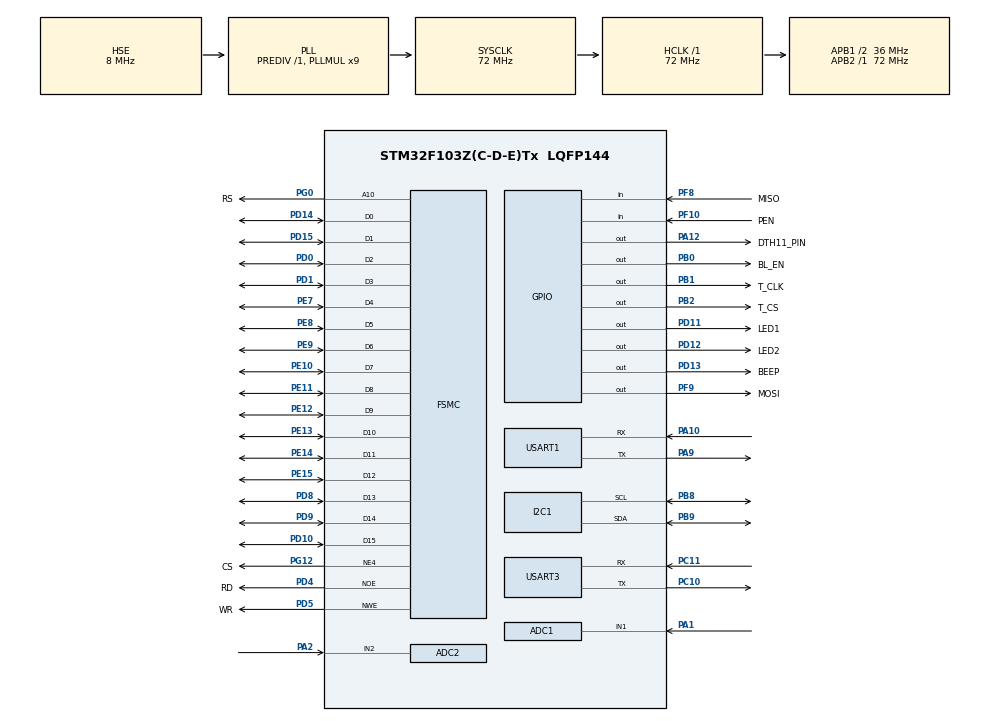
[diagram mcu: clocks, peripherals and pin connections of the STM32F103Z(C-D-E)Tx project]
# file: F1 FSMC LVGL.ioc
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ADC1.Channel-0\#ChannelRegularConversion=ADC_CHANNEL_1
ADC1.NbrOfConversionFlag=1
ADC1.Rank-0\#ChannelRegularConversion=1
ADC1.SamplingTime-0\#ChannelRegularConversion=ADC_SAMPLETIME_1CYCLE_5
ADC1.master=1
ADC2.Channel-1\#ChannelRegularConversion=ADC_CHANNEL_2
ADC2.NbrOfConversionFlag=1
ADC2.Rank-1\#ChannelRegularConversion=1
ADC2.SamplingTime-1\#ChannelRegularConversion=ADC_SAMPLETIME_1CYCLE_5
FREERTOS.HEAP_NUMBER=4
FREERTOS.Tasks01=defaultTask,24,128,StartDefaultTask,Default,NULL,Dynamic,NULL,NULL
FREERTOS.configCHECK_FOR_STACK_OVERFLOW=2
FREERTOS.configTOTAL_HEAP_SIZE=20480
FREERTOS.configUSE_MALLOC_FAILED_HOOK=1
FREERTOS.configUSE_TICK_HOOK=1
FSMC.AddressSetupTime1=0
FSMC.BusTurnAroundDuration1=0
FSMC.DataSetupTime1=26
FSMC.ExtendedAddressSetupTime1=0
FSMC.ExtendedBusTurnAroundDuration1=0
FSMC.ExtendedDataSetupTime1=1
FSMC.ExtendedMode1=FSMC_EXTENDED_MODE_ENABLE
Mcu.Family=STM32F1
Mcu.Name=STM32F103Z(C-D-E)Tx
Mcu.Package=LQFP144
NVIC.ADC1_2_IRQn=true\:5\:0\:false\:false\:true\:true\:true\:true\:true
NVIC.I2C1_ER_IRQn=true\:5\:0\:false\:false\:true\:true\:true\:true\:true
NVIC.I2C1_EV_IRQn=true\:5\:0\:false\:false\:true\:true\:true\:true\:true
NVIC.PriorityGroup=NVIC_PRIORITYGROUP_4
NVIC.RTC_IRQn=true\:5\:0\:false\:false\:true\:true\:true\:true\:true
NVIC.TIM1_UP_IRQn=true\:15\:0\:false\:false\:true\:false\:false\:true\:true
NVIC.TIM3_IRQn=true\:5\:0\:false\:false\:true\:true\:true\:true\:true
NVIC.TimeBase=TIM1_UP_IRQn
NVIC.TimeBaseIP=TIM1
NVIC.USART1_IRQn=true\:5\:0\:false\:false\:true\:true\:true\:true\:true
NVIC.USART3_IRQn=true\:5\:0\:false\:false\:true\:true\:true\:true\:true
OSC_IN.Mode=HSE-External-Oscillator
OSC_IN.Signal=RCC_OSC_IN
OSC_OUT.Mode=HSE-External-Oscillator
OSC_OUT.Signal=RCC_OSC_OUT
PA1.Signal=ADCx_IN1
PA10.Mode=Asynchronous
PA10.Signal=USART1_RX
PA12.GPIO_Label=DTH11_PIN
PA12.Signal=GPIO_Output
PA13.Mode=Serial_Wire
PA13.Signal=SYS_JTMS-SWDIO
PA14.Mode=Serial_Wire
PA14.Signal=SYS_JTCK-SWCLK
PA2.Signal=ADCx_IN2
PA9.Mode=Asynchronous
PA9.Signal=USART1_TX
PB0.GPIO_Label=BL_EN
PB0.GPIO_PuPd=GPIO_PULLUP
PB0.GPIO_Speed=GPIO_SPEED_FREQ_HIGH
PB0.Signal=GPIO_Output
PB1.GPIO_Label=T_CLK
PB1.GPIO_PuPd=GPIO_PULLUP
PB1.GPIO_Speed=GPIO_SPEED_FREQ_HIGH
PB1.PinState=GPIO_PIN_SET
PB1.Signal=GPIO_Output
PB2.GPIO_Label=T_CS
PB2.GPIO_PuPd=GPIO_PULLUP
PB2.GPIO_Speed=GPIO_SPEED_FREQ_HIGH
PB2.PinState=GPIO_PIN_SET
PB2.Signal=GPIO_Output
PB8.Mode=I2C
PB8.Signal=I2C1_SCL
PB9.Mode=I2C
PB9.Signal=I2C1_SDA
PC10.Mode=Asynchronous
PC10.Signal=USART3_TX
PC11.Mode=Asynchronous
PC11.Signal=USART3_RX
PC14-OSC32_IN.Mode=LSE-External-Oscillator
PC14-OSC32_IN.Signal=RCC_OSC32_IN
PC15-OSC32_OUT.Mode=LSE-External-Oscillator
PC15-OSC32_OUT.Signal=RCC_OSC32_OUT
PD0.Signal=FSMC_D2_DA2
PD1.Signal=FSMC_D3_DA3
PD10.Signal=FSMC_D15_DA15
PD11.GPIO_Label=LED1
PD11.GPIO_Speed=GPIO_SPEED_FREQ_MEDIUM
PD11.PinState=GPIO_PIN_SET
PD11.Signal=GPIO_Output
PD12.GPIO_Label=LED2
PD12.GPIO_Speed=GPIO_SPEED_FREQ_MEDIUM
PD12.PinState=GPIO_PIN_SET
PD12.Signal=GPIO_Output
PD13.GPIO_Label=BEEP
PD13.GPIO_Speed=GPIO_SPEED_FREQ_MEDIUM
PD13.PinState=GPIO_PIN_SET
PD13.Signal=GPIO_Output
PD14.Signal=FSMC_D0_DA0
PD15.Signal=FSMC_D1_DA1
PD4.GPIO_Label=RD
PD4.Signal=FSMC_NOE
PD5.GPIO_Label=WR
PD5.Signal=FSMC_NWE
PD8.Signal=FSMC_D13_DA13
PD9.Signal=FSMC_D14_DA14
PE10.Signal=FSMC_D7_DA7
PE11.Signal=FSMC_D8_DA8
PE12.Signal=FSMC_D9_DA9
PE13.Signal=FSMC_D10_DA10
PE14.Signal=FSMC_D11_DA11
PE15.Signal=FSMC_D12_DA12
PE7.Signal=FSMC_D4_DA4
PE8.Signal=FSMC_D5_DA5
PE9.Signal=FSMC_D6_DA6
PF10.GPIO_Label=PEN
PF10.GPIO_PuPd=GPIO_PULLUP
PF10.Signal=GPIO_Input
PF8.GPIO_Label=MISO
PF8.Signal=GPIO_Input
PF9.GPIO_Label=MOSI
PF9.GPIO_PuPd=GPIO_PULLUP
PF9.GPIO_Speed=GPIO_SPEED_FREQ_HIGH
PF9.PinState=GPIO_PIN_SET
PF9.Signal=GPIO_Output
PG0.GPIO_Label=RS
PG0.Signal=FSMC_A10
PG12.GPIO_Label=CS
PG12.Mode=NorPsramChipSelect4_1
PG12.Signal=FSMC_NE4
ProjectManager.HeapSize=0x200
ProjectManager.StackSize=0x400
ProjectManager.TargetToolchain=MDK-ARM V5.32
RCC.ADCPresc=RCC_ADCPCLK2_DIV6
RCC.AHBFreq_Value=72000000
RCC.APB1CLKDivider=RCC_HCLK_DIV2
RCC.APB1Freq_Value=36000000
RCC.APB1TimFreq_Value=72000000
RCC.APB2Freq_Value=72000000
RCC.APB2TimFreq_Value=72000000
RCC.HCLKFreq_Value=72000000
RCC.PLLMUL=RCC_PLL_MUL9
RCC.PLLSourceVirtual=RCC_PLLSOURCE_HSE
RCC.RTCClockSelection=RCC_RTCCLKSOURCE_LSE
RCC.SYSCLKFreq_VALUE=72000000
RCC.SYSCLKSource=RCC_SYSCLKSOURCE_PLLCLK
RCC.USBFreq_Value=72000000
RTC.Date=27
RTC.Hours=16
RTC.Minutes=46
RTC.Month=RTC_MONTH_AUGUST
RTC.WeekDay=RTC_WEEKDAY_TUESDAY
RTC.Year=24
SH.ADCx_IN1.0=ADC1_IN1,IN1
SH.ADCx_IN2.0=ADC2_IN2,IN2
SH.FSMC_A10.0=FSMC_A10,A10_1
SH.FSMC_D0_DA0.0=FSMC_D0,16b-d1
SH.FSMC_D10_DA10.0=FSMC_D10,16b-d1
SH.FSMC_D11_DA11.0=FSMC_D11,16b-d1
SH.FSMC_D12_DA12.0=FSMC_D12,16b-d1
SH.FSMC_D13_DA13.0=FSMC_D13,16b-d1
SH.FSMC_D14_DA14.0=FSMC_D14,16b-d1
SH.FSMC_D15_DA15.0=FSMC_D15,16b-d1
SH.FSMC_D1_DA1.0=FSMC_D1,16b-d1
SH.FSMC_D2_DA2.0=FSMC_D2,16b-d1
SH.FSMC_D3_DA3.0=FSMC_D3,16b-d1
SH.FSMC_D4_DA4.0=FSMC_D4,16b-d1
SH.FSMC_D5_DA5.0=FSMC_D5,16b-d1
SH.FSMC_D6_DA6.0=FSMC_D6,16b-d1
SH.FSMC_D7_DA7.0=FSMC_D7,16b-d1
SH.FSMC_D8_DA8.0=FSMC_D8,16b-d1
SH.FSMC_D9_DA9.0=FSMC_D9,16b-d1
SH.FSMC_NOE.0=FSMC_NOE,Lcd1
SH.FSMC_NWE.0=FSMC_NWE,Lcd1
TIM3.AutoReloadPreload=TIM_AUTORELOAD_PRELOAD_ENABLE
TIM3.Period=999
TIM3.Prescaler=71
USART1.VirtualMode=VM_ASYNC
USART3.VirtualMode=VM_ASYNC
VP_FREERTOS_VS_CMSIS_V2.Mode=CMSIS_V2
VP_RTC_No_RTC_Output.Mode=RTC_OUT_NO
VP_RTC_VS_RTC_Activate.Mode=RTC_Enabled
VP_RTC_VS_RTC_Calendar.Mode=RTC_Calendar
VP_SYS_VS_tim1.Mode=TIM1
VP_TIM3_VS_ClockSourceINT.Mode=Internal
board=custom

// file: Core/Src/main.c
/* USER CODE BEGIN Header */
/**
 ******************************************************************************
 * @file           : main.c
 * @brief          : Main program body
 ******************************************************************************
 * @attention
 *
 * Copyright (c) 2024 STMicroelectronics.
 * All rights reserved.
 *
 * This software is licensed under terms that can be found in the LICENSE file
 * in the root directory of this software component.
 * If no LICENSE file comes with this software, it is provided AS-IS.
 *
 ******************************************************************************
 */
/* USER CODE END Header */
#include "main.h"
#include "cmsis_os.h"
#include "adc.h"
#include "i2c.h"
#include "rtc.h"
#include "tim.h"
#include "usart.h"
#include "gpio.h"
#include "fsmc.h"

/* USER CODE BEGIN Includes */
#include "IH_Hardware_Init.h"
/* USER CODE END Includes */

void SystemClock_Config(void);
void MX_FREERTOS_Init(void);

int main(void)
{

  /* MCU Configuration--------------------------------------------------------*/

  /* Reset of all peripherals, Initializes the Flash interface and the Systick. */
  HAL_Init();

  /* Configure the system clock */
  SystemClock_Config();

  /* USER CODE BEGIN SysInit */
  __enable_irq();
  /* USER CODE END SysInit */

  /* Initialize all configured peripherals */
  MX_GPIO_Init();
  MX_FSMC_Init();
  MX_USART1_UART_Init();
  MX_TIM3_Init();
  MX_ADC1_Init();
  MX_RTC_Init();
  MX_ADC2_Init();
  MX_I2C1_Init();
  MX_USART3_UART_Init();

  /* Init scheduler */
  osKernelInitialize();

  /* Call init function for freertos objects (in cmsis_os2.c) */
  MX_FREERTOS_Init();

  /* Start scheduler */
  osKernelStart();

  /* We should never get here as control is now taken by the scheduler */

  /* Infinite loop */
  while (1)
  {

    /* USER CODE BEGIN 3 */
    printf("osKernel error\r\n");
    // lv_tick_inc(1);
    // lv_task_handler();
    // Delay_us(1);
  }
  /* USER CODE END 3 */
}

void SystemClock_Config(void)
{
  RCC_OscInitTypeDef RCC_OscInitStruct = {0};
  RCC_ClkInitTypeDef RCC_ClkInitStruct = {0};
  RCC_PeriphCLKInitTypeDef PeriphClkInit = {0};

  /** Initializes the RCC Oscillators according to the specified parameters
  * in the RCC_OscInitTypeDef structure.
  */
  RCC_OscInitStruct.OscillatorType = RCC_OSCILLATORTYPE_HSE|RCC_OSCILLATORTYPE_LSE;
  RCC_OscInitStruct.HSEState = RCC_HSE_ON;
  RCC_OscInitStruct.HSEPredivValue = RCC_HSE_PREDIV_DIV1;
  RCC_OscInitStruct.LSEState = RCC_LSE_ON;
  RCC_OscInitStruct.HSIState = RCC_HSI_ON;
  RCC_OscInitStruct.PLL.PLLState = RCC_PLL_ON;
  RCC_OscInitStruct.PLL.PLLSource = RCC_PLLSOURCE_HSE;
  RCC_OscInitStruct.PLL.PLLMUL = RCC_PLL_MUL9;
  if (HAL_RCC_OscConfig(&RCC_OscInitStruct) != HAL_OK)
  {
    Error_Handler();
  }

  /** Initializes the CPU, AHB and APB buses clocks
  */
  RCC_ClkInitStruct.ClockType = RCC_CLOCKTYPE_HCLK|RCC_CLOCKTYPE_SYSCLK
                              |RCC_CLOCKTYPE_PCLK1|RCC_CLOCKTYPE_PCLK2;
  RCC_ClkInitStruct.SYSCLKSource = RCC_SYSCLKSOURCE_PLLCLK;
  RCC_ClkInitStruct.AHBCLKDivider = RCC_SYSCLK_DIV1;
  RCC_ClkInitStruct.APB1CLKDivider = RCC_HCLK_DIV2;
  RCC_ClkInitStruct.APB2CLKDivider = RCC_HCLK_DIV1;

  if (HAL_RCC_ClockConfig(&RCC_ClkInitStruct, FLASH_LATENCY_2) != HAL_OK)
  {
    Error_Handler();
  }
  PeriphClkInit.PeriphClockSelection = RCC_PERIPHCLK_RTC|RCC_PERIPHCLK_ADC;
  PeriphClkInit.RTCClockSelection = RCC_RTCCLKSOURCE_LSE;
  PeriphClkInit.AdcClockSelection = RCC_ADCPCLK2_DIV6;
  if (HAL_RCCEx_PeriphCLKConfig(&PeriphClkInit) != HAL_OK)
  {
    Error_Handler();
  }
}

void HAL_TIM_PeriodElapsedCallback(TIM_HandleTypeDef *htim)
{
  if (htim->Instance == TIM1) {
    HAL_IncTick();
  }
}

void Error_Handler(void)
{
  __disable_irq();
  while (1)
  {
  }
}

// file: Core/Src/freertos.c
/* USER CODE BEGIN Header */
/**
 ******************************************************************************
 * File Name          : freertos.c
 * Description        : Code for freertos applications
 ******************************************************************************
 * @attention
 *
 * Copyright (c) 2024 STMicroelectronics.
 * All rights reserved.
 *
 * This software is licensed under terms that can be found in the LICENSE file
 * in the root directory of this software component.
 * If no LICENSE file comes with this software, it is provided AS-IS.
 *
 ******************************************************************************
 */
/* USER CODE END Header */

#include "FreeRTOS.h"
#include "task.h"
#include "main.h"
#include "cmsis_os.h"

/* USER CODE BEGIN Includes */
#include "IH_Task_Init.h"
/* USER CODE END Includes */

/* Definitions for defaultTask */
osThreadId_t defaultTaskHandle;
const osThreadAttr_t defaultTask_attributes = {
    .name = "defaultTask",
    .stack_size = 128 * 4,
    .priority = (osPriority_t)osPriorityNormal,
};

void StartDefaultTask(void *argument);

void MX_FREERTOS_Init(void); /* (MISRA C 2004 rule 8.1) */

/* Hook prototypes */
void vApplicationTickHook(void);
void vApplicationStackOverflowHook(xTaskHandle xTask, signed char *pcTaskName);
void vApplicationMallocFailedHook(void);

/* USER CODE BEGIN 3 */
void vApplicationTickHook(void)
{
  TaskTickHook();
}
/* USER CODE END 3 */

/* USER CODE BEGIN 4 */
void vApplicationStackOverflowHook(xTaskHandle xTask, signed char *pcTaskName)
{
  printf("Stack overflow detected for task '%s'!\n", pcTaskName);
}
/* USER CODE END 4 */

/* USER CODE BEGIN 5 */
void vApplicationMallocFailedHook(void)
{
  printf("Malloc failed\r\n");
}
/* USER CODE END 5 */

void MX_FREERTOS_Init(void)
{
  /* USER CODE BEGIN Init */
  User_Tasks_Init();
  /* USER CODE END Init */

  /* Create the thread(s) */
  /* creation of defaultTask */
  // defaultTaskHandle = osThreadNew(StartDefaultTask, NULL, &defaultTask_attributes);

}

void StartDefaultTask(void *argument)
{
  /* USER CODE BEGIN StartDefaultTask */
  /* Infinite loop */
  for (;;)
  {
    printf("start default task\r\n");
    osDelay(1);
  }
  /* USER CODE END StartDefaultTask */
}
